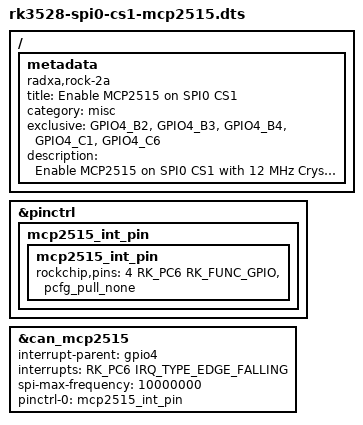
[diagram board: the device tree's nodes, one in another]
/dts-v1/;
/plugin/;

#include <dt-bindings/gpio/gpio.h>
#include <dt-bindings/pinctrl/rockchip.h>
#include <dt-bindings/interrupt-controller/irq.h>

/ {

	metadata {
		title = "Enable MCP2515 on SPI0 CS1";
		compatible = "radxa,rock-2a", "radxa,rock-2f", "radxa,medge-rk3528a-io";
		category = "misc";
		exclusive = "GPIO4_B2", "GPIO4_B3", "GPIO4_B4", "GPIO4_C1", "GPIO4_C6";
		description = "Enable MCP2515 on SPI0 CS1 with 12 MHz Crystal Oscillator.
INT=15";
	};
};

&pinctrl {
	mcp2515_int_pin {
		mcp2515_int_pin: mcp2515_int_pin {
			rockchip,pins = <4 RK_PC6 RK_FUNC_GPIO &pcfg_pull_none>;
		};
	};
};

&can_mcp2515 {
	interrupt-parent = <&gpio4>;
	interrupts = <RK_PC6 IRQ_TYPE_EDGE_FALLING>;
	spi-max-frequency = <10000000>;
	pinctrl-names = "default";
	pinctrl-0 = <&mcp2515_int_pin>;
};
